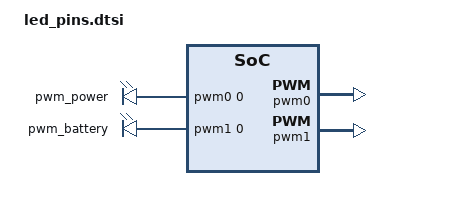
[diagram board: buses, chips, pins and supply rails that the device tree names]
/* Copyright 2026 The ChromiumOS Authors
 * Use of this source code is governed by a BSD-style license that can be
 * found in the LICENSE file.
 */

/ {
	pwmleds {
		compatible = "pwm-leds";
		/* Power LED, GPIOC3 */
		pwm_power: pwm-power {
			pwms = <&pwm0 0 PWM_HZ(100) PWM_POLARITY_NORMAL>;
		};

		/* Charge LED, GPIOC2 */
		pwm_battery: pwm-battery {
			pwms = <&pwm1 0 PWM_HZ(100) PWM_POLARITY_NORMAL>;
		};
	};

	led_pins: pwm-led-pins {
		compatible = "cros-ec,pwm-led-pins";

		battery_led: battery-led {
			led-id = "EC_LED_ID_BATTERY_LED";
			led-pwms = <&pwm_battery>;

			battery_led_off: color-off {
				led-color = "LED_OFF";
				led-values = <0>;
			};

			battery_led_amber: color-amber {
				led-color = "LED_AMBER";
				led-values = <100>;
			};
		};

		power_led: power-led {
			led-id = "EC_LED_ID_POWER_LED";
			led-pwms = <&pwm_power>;

			power_led_off: color-off {
				led-color = "LED_OFF";
				led-values = <0>;
			};

			power_led_white: color-white {
				led-color = "LED_WHITE";
				led-values = <100>;
			};
		};
	};
};

/* Power LED */
&pwm0 {
	status = "okay";
	clock-bus = "NPCX_CLOCK_BUS_LFCLK";
	pinctrl-0 = <&pwm0_gpc3>;
	pinctrl-names = "default";
};

/* Charge LED */
&pwm1 {
	status = "okay";
	clock-bus = "NPCX_CLOCK_BUS_LFCLK";
	pinctrl-0 = <&pwm1_gpc2>;
	pinctrl-names = "default";
};
